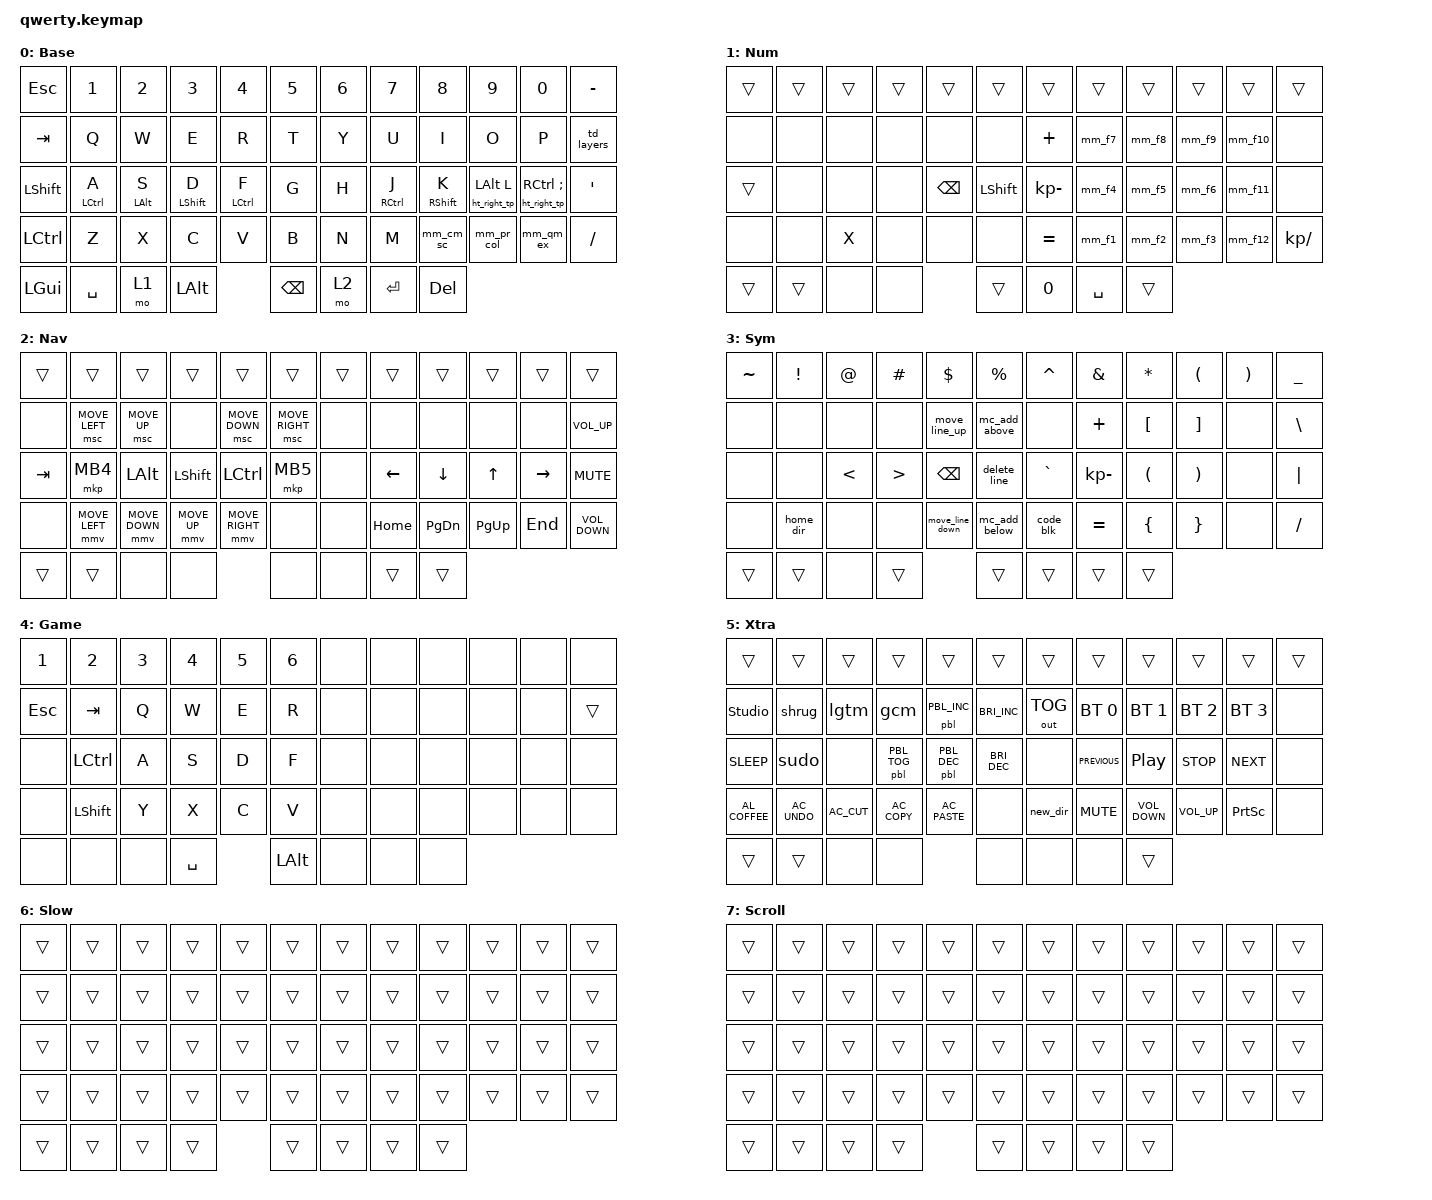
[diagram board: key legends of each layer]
/* upstream bindings and behaviors */
#include <behaviors.dtsi>
#include <dt-bindings/zmk/bt.h>
#include <dt-bindings/zmk/keys.h>
#include <dt-bindings/zmk/mouse.h>
#include <dt-bindings/zmk/outputs.h>
#include <behaviors/mouse_keys.dtsi>
#include <dt-bindings/zmk/ext_power.h>

/* local overlays */
#include "keymap_features/prospector_brightness.dtsi"
#include "keymap_features/macros.dtsi"
#include "keymap_features/behaviors.dtsi"
#include "keymap_features/combos.dtsi"

/ {
/* --- KEYMAP CONFIG --- */
// ╭──────┬──────┬──────┬──────┬──────┬──────╮  ╭──────┬──────┬──────┬──────┬──────┬──────╮
//    00     01     02     03    04      05        06     07     08     09     10     11
// ├──────┼──────┼──────┼──────┼──────┼──────┤  ├──────┼──────┼──────┼──────┼──────┼──────┤
//    12     13     14     15    16      17        18     19     20     21     22     23
// ├──────┼──────┼──────┼──────┼──────┼──────┤  ├──────┼──────┼──────┼──────┼──────┼──────┤
//    24     25     26     27    28      29        30     31     32     33     34     35
// ├──────┼──────┼──────┼──────┼──────┼──────┤  ├──────┼──────┼──────┼──────┼──────┼──────┤
//    36     37     38     39    40      41        42     43     44     45     46     47
// ╰──────┴──────┴──────┼──────┼──────┼──────┤  ├──────┼──────┼──────┴──────┴──────┴──────╯
//           48     49     50     51     52        53     54     55
//        ╰──────┴──────┴──────┴──────┴──────╯  ╰──────┴──────┴──────╯
// #define BASE    0
// #define NUM     1
// #define NAV     2
// #define SYM     3
// #define GAME    4
// #define EXTRAS  5
// #define SLOW    6
// #define SCROLL  7

// This shared keymap builds for prospector and non-prospector firmwares. 
// This stubs the key bindings that are contained in the prospector module
// so non-prospector firmware can build.
#ifndef CONFIG_SHIELD_PROSPECTOR_ADAPTER
    behaviors {
        /omit-if-no-ref/ pbl: prospector_brightness_stub {
            compatible = "zmk,behavior-macro-two-param";
            #binding-cells = <2>;
            bindings = <&none>;
        };
    };
#endif

    keymap {
        compatible = "zmk,keymap";
        BASE {
            display-name = "Base";
            bindings = <
    &kp ESC         &kp N1   &kp N2   &kp N3   &kp N4   &kp N5   &kp N6      &kp N7   &kp N8   &kp N9   &kp N0   &kp MINUS
    &kp TAB  &kp Q  &kp W  &kp E  &kp R  &kp T    &kp Y  &kp U  &kp I  &kp O  &kp P  &td_layers
    &kp LSHFT  &ht_left LCTRL A  &ht_left LALT S  &ht_left LSHFT D  &ht_left LCTRL F  &kp G    &kp H  &ht_right RCTRL J  &ht_right RSHFT K  &ht_right_tp LALT L  &ht_right_tp RCTRL SEMICOLON  &kp SQT
    &kp LCTRL  &kp Z               &kp X  &kp C  &kp V  &kp B    &kp N  &kp M  &mm_cm_sc  &mm_pr_col  &mm_qm_ex  &kp FSLH
        &kp LGUI  &kp SPACE  &mo 1  &kp LALT  &kp BACKSPACE    &mo 2  &kp ENTER  &kp DEL
            >;
        };

        NUM {
            display-name = "Num";
            bindings = <
&trans  &trans  &trans  &trans  &trans  &trans    &trans      &trans   &trans   &trans   &trans   &trans
&none   &none   &none   &none   &none   &none     &kp PLUS    &mm_f7   &mm_f8   &mm_f9   &mm_f10  &none
&trans  &none   &none   &none   &kp BACKSPACE  &kp LSHIFT    &kp KP_MINUS  &mm_f4  &mm_f5  &mm_f6  &mm_f11  &none
&none   &none   &kp X   &none   &none   &none     &kp EQUAL   &mm_f1   &mm_f2   &mm_f3   &mm_f12  &kp KP_SLASH
&trans  &trans  &none   &none   &trans            &kp N0      &kp SPACE  &trans
            >;
        };

        NAV {
            display-name = "Nav";
            bindings = <
&trans   &trans          &trans         &trans        &trans          &trans            &trans   &trans          &trans       &trans          &trans           &trans
&none    &msc MOVE_LEFT  &msc MOVE_UP   &none         &msc MOVE_DOWN  &msc MOVE_RIGHT   &none    &none           &none        &none           &none            &kp C_VOLUME_UP
&kp TAB  &mkp MB4        &kp LALT       &kp LSHFT     &kp LCTRL       &mkp MB5          &none    &kp LEFT_ARROW  &kp DOWN     &kp UP          &kp RIGHT_ARROW  &kp K_MUTE
&none    &mmv MOVE_LEFT  &mmv MOVE_DOWN &mmv MOVE_UP  &mmv MOVE_RIGHT &none             &none    &kp HOME        &kp PG_DN    &kp PG_UP       &kp END          &kp C_VOLUME_DOWN
&trans   &trans          &none          &none          &none            &none             &trans           &trans
            >;
        };

        SYM {
            display-name = "Sym";
            bindings = <
&kp TILDE  &kp EXCL   &kp AT   &kp HASH  &kp DLLR         &kp PRCNT      &kp CARET  &kp AMPS      &kp ASTRK  &kp LPAR  &kp RPAR  &kp UNDER
&none      &none      &none    &none     &move_line_up    &mc_add_above  &none      &kp PLUS      &kp LBKT   &kp RBKT  &none     &kp BSLH
&none      &none      &kp LT   &kp GT    &kp BACKSPACE    &delete_line   &kp GRAVE  &kp KP_MINUS  &kp LPAR   &kp RPAR  &none     &kp PIPE
&none      &home_dir  &none    &none     &move_line_down  &mc_add_below  &code_blk  &kp EQUAL     &kp LBRC   &kp RBRC  &none     &kp FSLH
&trans  &trans      &none     &trans     &trans            &trans         &trans     &trans
            >;
        };

        GAME {
            display-name = "Game";
            bindings = <
&kp N1  &kp N2  &kp N3  &kp N4  &kp N5  &kp N6    &none  &none  &none  &none  &none  &none
&kp ESC  &kp TAB    &kp Q  &kp W  &kp E  &kp R     &none  &none  &none  &none  &none  &trans
&none    &kp LCTRL  &kp A  &kp S  &kp D  &kp F     &none  &none  &none  &none  &none  &none
&none    &kp LSHFT  &kp Y  &kp X  &kp C  &kp V     &none  &none  &none  &none  &none  &none
&none    &none      &none  &kp SPACE  &kp LEFT_ALT  &none  &none  &none
            >;
        };

        EXTRAS {
            display-name = "Xtra";
            bindings = <
&trans           &trans          &trans          &trans          &trans          &trans                    &trans        &trans          &trans             &trans            &trans           &trans
&studio_unlock   &shrug          &lgtm           &gcm            &pbl PBL_INC    &kp C_BRIGHTNESS_INC      &out OUT_TOG  &bt BT_SEL 0    &bt BT_SEL 1       &bt BT_SEL 2      &bt BT_SEL 3     &none
&kp C_SLEEP      &sudo           &none           &pbl PBL_TOG    &pbl PBL_DEC    &kp C_BRIGHTNESS_DEC      &none         &kp C_PREVIOUS  &kp C_PLAY_PAUSE   &kp C_STOP        &kp C_NEXT       &none
&kp C_AL_COFFEE  &kp C_AC_UNDO   &kp C_AC_CUT    &kp C_AC_COPY   &kp C_AC_PASTE  &none                     &new_dir      &kp K_MUTE      &kp C_VOLUME_DOWN  &kp C_VOLUME_UP   &kp PRINTSCREEN  &none
&trans           &trans          &none           &none           &none             &none                     &none         &trans
            >;
        };

        SLOW {
            display-name = "Slow";
            bindings = <
// ╭────────┬────────┬────────┬────────┬────────┬────────╮  ╭────────┬────────┬────────┬────────┬────────┬────────╮
    &trans    &trans   &trans   &trans   &trans   &trans      &trans   &trans   &trans   &trans   &trans   &trans
// ├────────┼────────┼────────┼────────┼────────┼────────┤  ├────────┼────────┼────────┼────────┼────────┼────────┤
    &trans    &trans   &trans   &trans   &trans   &trans      &trans   &trans   &trans   &trans   &trans   &trans
// ├────────┼────────┼────────┼────────┼────────┼────────┤  ├────────┼────────┼────────┼────────┼────────┼────────┤
    &trans    &trans   &trans   &trans   &trans   &trans      &trans   &trans   &trans   &trans   &trans   &trans
// ├────────┼────────┼────────┼────────┼────────┼────────┤  ├────────┼────────┼────────┼────────┼────────┼────────┤
    &trans    &trans   &trans   &trans   &trans   &trans      &trans   &trans   &trans   &trans   &trans   &trans
// ╰────────┴────────┴────────┼────────┼────────┼────────┼────────┼────────╮  ╭────────┼────────┼────────┴────────┴────────┴────────╯
                                  &trans   &trans   &trans   &trans   &trans      &trans   &trans   &trans
                             // ╰────────┴────────┴────────┴────────┴────────╯  ╰────────┴────────┴────────╯
            >;
        };

        SCROLL {
            display-name = "Scroll";
            bindings = <
// ╭────────┬────────┬────────┬────────┬────────┬────────╮  ╭────────┬────────┬────────┬────────┬────────┬────────╮
    &trans    &trans   &trans   &trans   &trans   &trans      &trans   &trans   &trans   &trans   &trans   &trans
// ├────────┼────────┼────────┼────────┼────────┼────────┤  ├────────┼────────┼────────┼────────┼────────┼────────┤
    &trans    &trans   &trans   &trans   &trans   &trans      &trans   &trans   &trans   &trans   &trans   &trans
// ├────────┼────────┼────────┼────────┼────────┼────────┤  ├────────┼────────┼────────┼────────┼────────┼────────┤
    &trans    &trans   &trans   &trans   &trans   &trans      &trans   &trans   &trans   &trans   &trans   &trans
// ├────────┼────────┼────────┼────────┼────────┼────────┤  ├────────┼────────┼────────┼────────┼────────┼────────┤
    &trans    &trans   &trans   &trans   &trans   &trans      &trans   &trans   &trans   &trans   &trans   &trans
// ╰────────┴────────┴────────┼────────┼────────┼────────┼────────┼────────╮  ╭────────┼────────┼────────┴────────┴────────┴────────╯
                                  &trans   &trans   &trans   &trans   &trans      &trans   &trans   &trans
                             // ╰────────┴────────┴────────┴────────┴────────╯  ╰────────┴────────┴────────╯
            >;
        };
    };
};
